# BlueNRG_LPS register map
File version: 1.0
CPU: CM0+ r0p0, little endian, no MPU, no FPU, 2 interrupt priority bits
Registers are 32-bit, read-write, reset 0x0 unless marked. A register's access mark holds for its fields unless they carry their own. Offsets are from the block's base; [hi:lo] are bit positions.

## RCC — Reset and clock control
Base 0x48400000
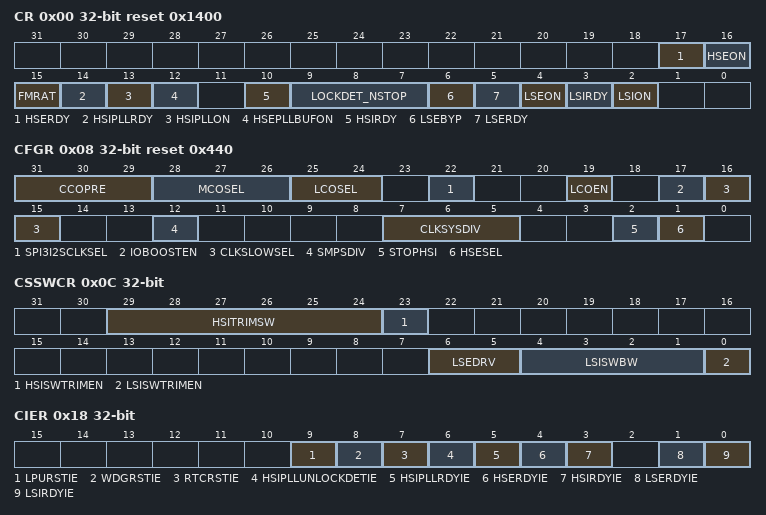
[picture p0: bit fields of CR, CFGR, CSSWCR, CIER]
0x00 CR reset 0x1400 — Clock control register
  [17] HSERDY ro — External High Speed clock flag.
  [16] HSEON — External High Speed clock enable.
  [15] FMRAT
  [14] HSIPLLRDY — Internal High Speed clock PLL flag. This bit is set by hardware to indicate that the RC64MPLL pll is locked
  [13] HSIPLLON — Internal High Speed clock PLL enable
  [12] HSEPLLBUFON — External high speed clock buffer for PLL RF2G4 enable.
  [10] HSIRDY ro — HSI clock ready flag
  [9:7] LOCKDET_NSTOP
  [6] LSEBYP — External Low Speed clock bypass.
  [5] LSERDY ro — External Low Speed clock flag
  [4] LSEON — External Low Speed clock enable
  [3] LSIRDY ro — Internal Low Speed clock flag
  [2] LSION — Internal low speed RC clock enable
0x08 CFGR reset 0x440 — Clock configuration register
  [31:29] CCOPRE — Configurable Clock Output Prescaler
  [28:26] MCOSEL — Microcontroller clock output
  [25:24] LCOSEL — Low speed Configurable Clock Output Selection
  [22] SPI3I2SCLKSEL — Selection of I2s clock for SPI2 IP
  [19] LCOEN — LCO enable on PA10 also in deepstop.
  [17] IOBOOSTEN — IO BOOSTER external clock enable
  [16:15] CLKSLOWSEL — low speed clock source selection
  [12] SMPSDIV — SMPs clock prescaling factor
  [7:5] CLKSYSDIV — system clock divided factor from HSI_64M
  [2] STOPHSI — RC64MPLL clock source stop request
  [1] HSESEL — Clock source selection request.
0x0C CSSWCR — Clocks Sources Software Calibration register
  [29:24] HSITRIMSW — High speed clock trimming set by software
  [23] HSISWTRIMEN — High speed clock software trimming enable
  [6:5] LSEDRV — external 32 kHz crystal GM
  [4:1] LSISWBW — Low speed internal RC trimming value set by software
  [0] LSISWTRIMEN — Low speed internal RC software trimming enable
0x18 CIER — Clock interrupt enable register
  [9] LPURSTIE — LPUART reset release interrupt enable.
  [8] WDGRSTIE — Watchdog reset release interrupt enable.
  [7] RTCRSTIE — RTC reset release interrupt enable.
  [6] HSIPLLUNLOCKDETIE — HSI PLL unlock detection interrupt enable.
  [5] HSIPLLRDYIE — HSI PLLSYs ready interrupt enable
  [4] HSERDYIE — HSE ready interrupt enable
  [3] HSIRDYIE — HSI ready interrupt enable
  [1] LSERDYIE — LSE ready interrupt enable
  [0] LSIRDYIE — LSI1 ready interrupt enable
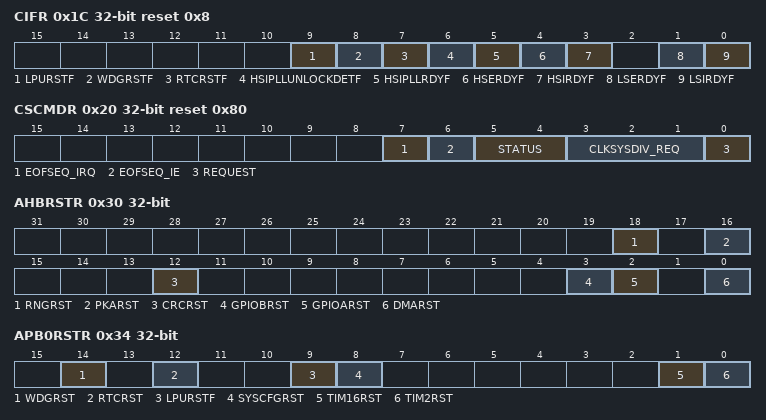
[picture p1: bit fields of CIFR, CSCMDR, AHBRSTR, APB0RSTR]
0x1C CIFR reset 0x8 — Clock interrupt flag register
  [9] LPURSTF — LPUART reset release flag.
  [8] WDGRSTF — Watchdog reset release flag.
  [7] RTCRSTF — RTC reset release flag.
  [6] HSIPLLUNLOCKDETF — HSI PLL unlock detection flag.
  [5] HSIPLLRDYF — HSI PLL ready flag
  [4] HSERDYF — HSE ready interrupt flag
  [3] HSIRDYF — HSI ready interrupt flag
  [1] LSERDYF — LSE ready interrupt flag
  [0] LSIRDYF — LSI1 ready interrupt flag
0x20 CSCMDR reset 0x80 — This register allows switching the CPU system clock frequency safely while the MR_BLE is active.
  [7] EOFSEQ_IRQ — End of sequence flag.
  [6] EOFSEQ_IE — End of sequence interrupt enable.
  [5:4] STATUS — Status of the switching sequence.
  [3:1] CLKSYSDIV_REQ — System clock requested/targeted frequency.
  [0] REQUEST — Request to switch the system clock frequency.
0x30 AHBRSTR — AHB0 macro cells reset register
  [18] RNGRST — RNG reset
  [16] PKARST — PKA reset
  [12] CRCRST — CRC reset
  [3] GPIOBRST — IO controller for port A reset
  [2] GPIOARST — IO controller for port B reset
  [0] DMARST — DMA and DMAMUX reset
0x34 APB0RSTR — APB0 macro cells reset register
  [14] WDGRST — Watchdog reset
  [12] RTCRST — RTC reset
  [9] LPURSTF — LPUART reset release flag.Bit 2 TIM17RST: TIM17 reset.
  [8] SYSCFGRST — system controller reset
  [1] TIM16RST — TIM16 reset.
  [0] TIM2RST — TIM2 reset.
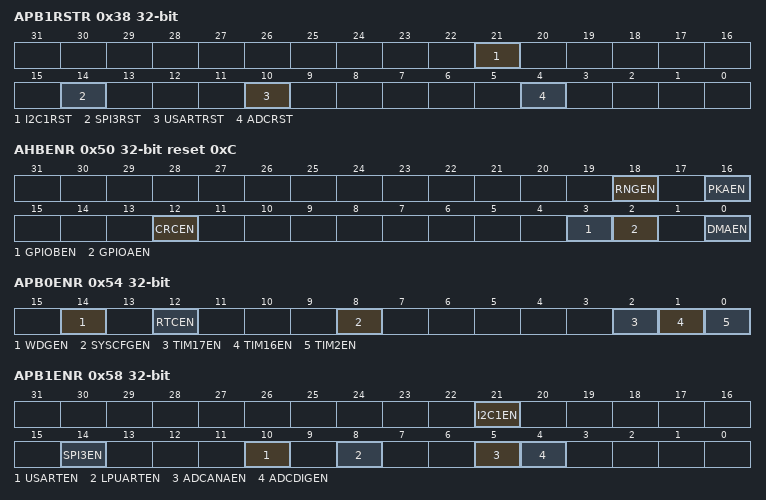
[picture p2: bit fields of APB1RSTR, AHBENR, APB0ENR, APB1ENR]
0x38 APB1RSTR — APB1 peripheral reset register 1
  [21] I2C1RST — I2C1 reset
  [14] SPI3RST — SPI3 reset
  [10] USARTRST — USARTRST: USART reset
  [4] ADCRST — ADC reset
0x40 APB2RSTR — APB2 peripheral reset register 2
  [0] MRBLERST — MR_BLE Bluetooth radio reset
0x50 AHBENR reset 0xC — AHB0 macro cells clock enable register
  [18] RNGEN — RNG clock enable
  [16] PKAEN — PKAEN: PKA enable
  [12] CRCEN — CRCEN: CRC enable
  [3] GPIOBEN — IO controller for port B enable
  [2] GPIOAEN — IO controller for port A enable
  [0] DMAEN — DMA and DMAMUX enable
0x54 APB0ENR — APB0 macro cells clock enable register
  [14] WDGEN — Watchdog enable.
  [12] RTCEN — RTC enable.
  [8] SYSCFGEN — system controller enable.
  [2] TIM17EN — TIM17 enable.
  [1] TIM16EN — TIM16 enable.
  [0] TIM2EN — TIM2 enable.
0x58 APB1ENR
  [21] I2C1EN — CPU1 I2C1 clock enable
  [14] SPI3EN — CPU1 SPI3 clock enable
  [10] USARTEN — USART enable
  [8] LPUARTEN — LPUART enable
  [5] ADCANAEN
  [4] ADCDIGEN
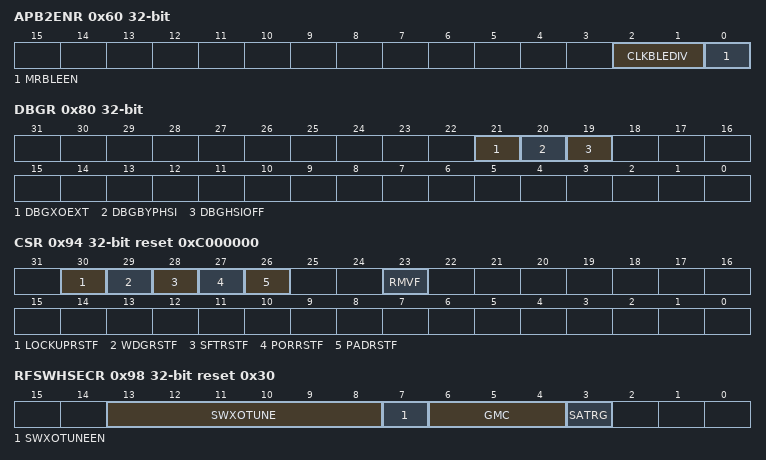
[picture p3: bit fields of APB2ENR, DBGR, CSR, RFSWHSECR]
0x60 APB2ENR
  [2:1] CLKBLEDIV — MR_BLE (Bluetooth Low Energy radio) clock frequency selection when RCC_APB2ENR.MRBLEEN=1.
  [0] MRBLEEN — MR_BLE (Bluetooth radio) enable.
0x80 DBGR — This register is planned for debug use-case only.
  [21] DBGXOEXT — Used for debug mode only.
  [20] DBGBYPHSI — Used for debug mode only.
  [19] DBGHSIOFF — Used for debug mode only.
0x94 CSR reset 0xC000000
  [30] LOCKUPRSTF ro — CPU lockup reset flag
  [29] WDGRSTF ro — Watchdog reset flag
  [28] SFTRSTF ro — Software reset flag
  [27] PORRSTF ro — Power-On reset flag
  [26] PADRSTF ro — NRSTn pad reset flag.
  [23] RMVF — Remove Flag reset
0x98 RFSWHSECR reset 0x30 — RF Software High Speed External register
  [13:8] SWXOTUNE — RF HSE capacitor bank tuning value set by software
  [7] SWXOTUNEEN — RF HSE software capacitor bank tuning enable
  [6:4] GMC — High speed external IO current control
  [3] SATRG — Sense Amplifier Threshold
0x9C RFHSECR ro — RF High Speed External register
  [5:0] XOTUNE — RF-HSE capacitor bank tuning
